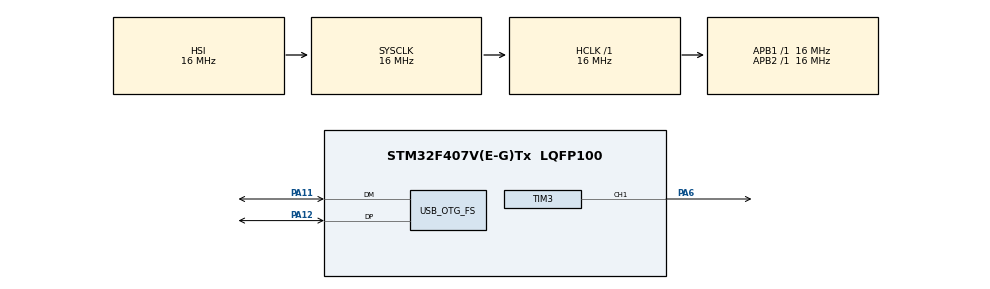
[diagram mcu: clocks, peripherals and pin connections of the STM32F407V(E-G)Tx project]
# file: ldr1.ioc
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Mcu.Family=STM32F4
Mcu.Name=STM32F407V(E-G)Tx
Mcu.Package=LQFP100
NVIC.OTG_FS_IRQn=true\:0\:0\:false\:false\:true\:false\:true\:true
NVIC.PriorityGroup=NVIC_PRIORITYGROUP_4
PA11.Mode=Device_Only
PA11.Signal=USB_OTG_FS_DM
PA12.Mode=Device_Only
PA12.Signal=USB_OTG_FS_DP
PA13.Mode=Serial_Wire
PA13.Signal=SYS_JTMS-SWDIO
PA14.Mode=Serial_Wire
PA14.Signal=SYS_JTCK-SWCLK
PA6.Signal=S_TIM3_CH1
PH0-OSC_IN.Mode=HSE-External-Oscillator
PH0-OSC_IN.Signal=RCC_OSC_IN
PH1-OSC_OUT.Mode=HSE-External-Oscillator
PH1-OSC_OUT.Signal=RCC_OSC_OUT
ProjectManager.HeapSize=0x200
ProjectManager.StackSize=0x400
ProjectManager.TargetToolchain=STM32CubeIDE
RCC.48MHZClocksFreq_Value=48000000
RCC.AHBFreq_Value=16000000
RCC.APB1Freq_Value=16000000
RCC.APB2Freq_Value=16000000
RCC.CortexFreq_Value=16000000
RCC.HSE_VALUE=8000000
RCC.HSI_VALUE=16000000
RCC.LSE_VALUE=32768
RCC.PLLM=8
RCC.SYSCLKFreq_VALUE=16000000
RCC.VCOOutputFreq_Value=192000000
SH.S_TIM3_CH1.0=TIM3_CH1,PWM Generation1 CH1
TIM3.AutoReloadPreload=TIM_AUTORELOAD_PRELOAD_ENABLE
TIM3.Channel-PWM\ Generation1\ CH1=TIM_CHANNEL_1
TIM3.Period=1000-1
TIM3.Pulse-PWM\ Generation1\ CH1=500-1
USB_DEVICE.CLASS_NAME_FS=CDC
USB_DEVICE.VirtualMode-CDC_FS=Cdc
USB_DEVICE.VirtualModeFS=Cdc_FS
USB_OTG_FS.VirtualMode=Device_Only
VP_USB_DEVICE_VS_USB_DEVICE_CDC_FS.Mode=CDC_FS
board=custom

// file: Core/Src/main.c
/* USER CODE BEGIN Header */
/**
  ******************************************************************************
  * @file           : main.c
  * @brief          : Main program body
  ******************************************************************************
  * @attention
  *
  * Copyright (c) 2023 STMicroelectronics.
  * All rights reserved.
  *
  * This software is licensed under terms that can be found in the LICENSE file
  * in the root directory of this software component.
  * If no LICENSE file comes with this software, it is provided AS-IS.
  *
  ******************************************************************************
  */
/* USER CODE END Header */
#include "main.h"
#include "usb_device.h"

/* USER CODE BEGIN Includes */
#include "usbd_cdc_if.h"
/* USER CODE END Includes */

/* USER CODE BEGIN PTD */
uint8_t receivebuffer[64];
/* USER CODE END PTD */

TIM_HandleTypeDef htim3;

/* USER CODE BEGIN PV */
int monitor = 0;
/* USER CODE END PV */

void SystemClock_Config(void);
static void MX_GPIO_Init(void);
static void MX_TIM3_Init(void);

int main(void)
{

  /* MCU Configuration--------------------------------------------------------*/

  /* Reset of all peripherals, Initializes the Flash interface and the Systick. */
  HAL_Init();

  /* Configure the system clock */
  SystemClock_Config();

  /* Initialize all configured peripherals */
  MX_GPIO_Init();
  MX_USB_DEVICE_Init();
  MX_TIM3_Init();
  /* USER CODE BEGIN 2 */
HAL_TIM_PWM_Start(&htim3, TIM_CHANNEL_1);
  /* USER CODE END 2 */

  /* Infinite loop */
  /* USER CODE BEGIN WHILE */
  while (1)
  {
	  if (htim3.Instance->CNT > htim3.Instance->CCR1)
	  {
		  monitor = 1;
	  }
	  else
	  {
		  monitor = 0;
	  }

	  if (strlen(receivebuffer) > 0)
	  {
		  if (receivebuffer[0] == 't')
		  {
			  htim3.Instance->ARR=atoi(receivebuffer + 1);
		  }
		  else if (receivebuffer[0] == 'd')
		  {
			  htim3.Instance->CCR1=atoi(receivebuffer + 1);
		  }
		  memset(receivebuffer, 0, 64);
	  }

    /* USER CODE END WHILE */

  }
}

void SystemClock_Config(void)
{
  RCC_OscInitTypeDef RCC_OscInitStruct = {0};
  RCC_ClkInitTypeDef RCC_ClkInitStruct = {0};

  /** Configure the main internal regulator output voltage
  */
  __HAL_RCC_PWR_CLK_ENABLE();
  __HAL_PWR_VOLTAGESCALING_CONFIG(PWR_REGULATOR_VOLTAGE_SCALE1);

  /** Initializes the RCC Oscillators according to the specified parameters
  * in the RCC_OscInitTypeDef structure.
  */
  RCC_OscInitStruct.OscillatorType = RCC_OSCILLATORTYPE_HSI|RCC_OSCILLATORTYPE_HSE;
  RCC_OscInitStruct.HSEState = RCC_HSE_ON;
  RCC_OscInitStruct.HSIState = RCC_HSI_ON;
  RCC_OscInitStruct.HSICalibrationValue = RCC_HSICALIBRATION_DEFAULT;
  RCC_OscInitStruct.PLL.PLLState = RCC_PLL_ON;
  RCC_OscInitStruct.PLL.PLLSource = RCC_PLLSOURCE_HSE;
  RCC_OscInitStruct.PLL.PLLM = 8;
  RCC_OscInitStruct.PLL.PLLN = 192;
  RCC_OscInitStruct.PLL.PLLP = RCC_PLLP_DIV2;
  RCC_OscInitStruct.PLL.PLLQ = 4;
  if (HAL_RCC_OscConfig(&RCC_OscInitStruct) != HAL_OK)
  {
    Error_Handler();
  }

  /** Initializes the CPU, AHB and APB buses clocks
  */
  RCC_ClkInitStruct.ClockType = RCC_CLOCKTYPE_HCLK|RCC_CLOCKTYPE_SYSCLK
                              |RCC_CLOCKTYPE_PCLK1|RCC_CLOCKTYPE_PCLK2;
  RCC_ClkInitStruct.SYSCLKSource = RCC_SYSCLKSOURCE_HSI;
  RCC_ClkInitStruct.AHBCLKDivider = RCC_SYSCLK_DIV1;
  RCC_ClkInitStruct.APB1CLKDivider = RCC_HCLK_DIV1;
  RCC_ClkInitStruct.APB2CLKDivider = RCC_HCLK_DIV1;

  if (HAL_RCC_ClockConfig(&RCC_ClkInitStruct, FLASH_LATENCY_0) != HAL_OK)
  {
    Error_Handler();
  }
}

static void MX_TIM3_Init(void)
{

  TIM_MasterConfigTypeDef sMasterConfig = {0};
  TIM_OC_InitTypeDef sConfigOC = {0};

  htim3.Instance = TIM3;
  htim3.Init.Prescaler = 0;
  htim3.Init.CounterMode = TIM_COUNTERMODE_UP;
  htim3.Init.Period = 1000-1;
  htim3.Init.ClockDivision = TIM_CLOCKDIVISION_DIV1;
  htim3.Init.AutoReloadPreload = TIM_AUTORELOAD_PRELOAD_ENABLE;
  if (HAL_TIM_PWM_Init(&htim3) != HAL_OK)
  {
    Error_Handler();
  }
  sMasterConfig.MasterOutputTrigger = TIM_TRGO_RESET;
  sMasterConfig.MasterSlaveMode = TIM_MASTERSLAVEMODE_DISABLE;
  if (HAL_TIMEx_MasterConfigSynchronization(&htim3, &sMasterConfig) != HAL_OK)
  {
    Error_Handler();
  }
  sConfigOC.OCMode = TIM_OCMODE_PWM1;
  sConfigOC.Pulse = 500-1;
  sConfigOC.OCPolarity = TIM_OCPOLARITY_HIGH;
  sConfigOC.OCFastMode = TIM_OCFAST_DISABLE;
  if (HAL_TIM_PWM_ConfigChannel(&htim3, &sConfigOC, TIM_CHANNEL_1) != HAL_OK)
  {
    Error_Handler();
  }
  HAL_TIM_MspPostInit(&htim3);

}

static void MX_GPIO_Init(void)
{

  /* GPIO Ports Clock Enable */
  __HAL_RCC_GPIOH_CLK_ENABLE();
  __HAL_RCC_GPIOA_CLK_ENABLE();

}

void Error_Handler(void)
{
  __disable_irq();
  while (1)
  {
  }
}
